# DMA register map
Vendor: Texas Instruments
Peripheral module from a debugger description file (folder DRA74xP_75xP_76xP_77xP).
Registers are 32-bit, access per field, reset 0x0 unless marked. A register's access mark holds for its fields unless they carry their own. Offsets are as the file gives them; lines under a group give offsets from that group; [hi:lo] are bit positions; {n}, {i} and the like mark numbered series; 'fields as' and 'values as' point back to an identical list; <NAME> marks a mode.

## DMA
0x00 SIMCOP_DMA_REVISION ro reset not defined — IP Revision Identifier (X.Y.R) Used by software to track features, bugs, and compatibility
  [31:0] REVISION — IP Revision
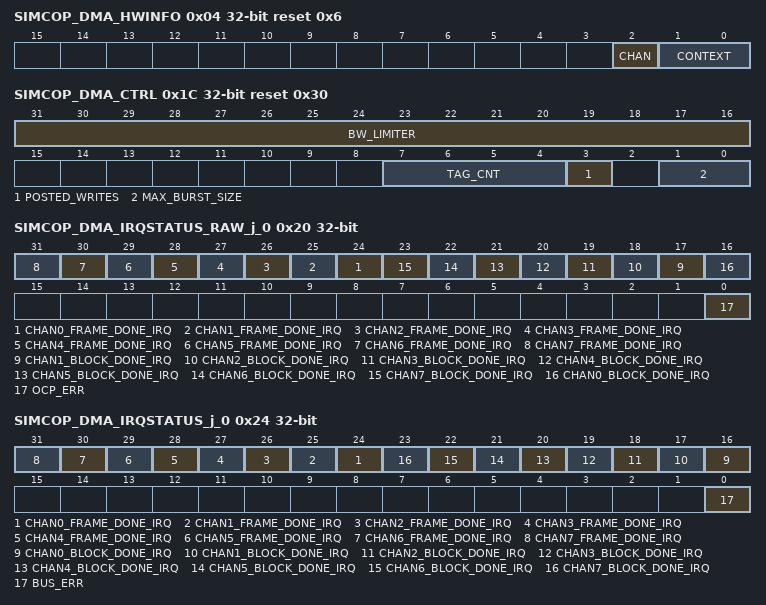
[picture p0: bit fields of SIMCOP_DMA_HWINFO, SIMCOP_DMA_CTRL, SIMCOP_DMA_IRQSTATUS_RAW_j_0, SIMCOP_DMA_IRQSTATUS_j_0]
0x04 SIMCOP_DMA_HWINFO ro reset 0x6 — Information about the IP module's hardware configuration, i.e. typically the module's HDL generics.
  [2] CHAN — Logical channels
    0=CHAN_0_r (4); 1=CHAN_1_r (8)
  [1:0] CONTEXT — Maximum outstanding OCP transactions
    0=CONTEXT_0_r (4); 1=CONTEXT_1_r (8); 2=CONTEXT_2_r (16)
0x10 SIMCOP_DMA_SYSCONFIG reset 0x20 — Clock management configuration
  [5:4] STANDBYMODE rw — Configuration of the local initiator state management mode. By definition, initiator may generate read/write transaction as long as it is out of STANDBY state.
    0=Force-standby mode: local initiator is unconditionally placed in standby state. Backup mode, for debug only.; 1=No-standby mode: local initiator is unconditionally placed out of standby state. Backup mode, for debug only.; 2=Smart_standby_mode; 3=Smart_standby_mode
0x18 SIMCOP_DMA_IRQ_EOI — End Of Interrupt number specification
  [1:0] LINE_NUMBER rw — Software End Of Interrupt (EOI) control. Write number of interrupt output.
    0=READ0 (Reads always 0 (no EOI memory)); 1=EOI1 (EOI for interrupt output line #1)
0x1C SIMCOP_DMA_CTRL reset 0x30
  [31:16] BW_LIMITER rw — SIMCOP DMA guarantees that there are at least BW_LIMITER functional clock cycles between two OCP requests. No IDLE cycles are inserted during an OCP transaction. This parameter could be used to reduce traffic generated by the SIMCOP DMA for non timing critical applications. Doing so leaves more BW for other system initiators. Default value corresponds to maximum performance.
  [7:4] TAG_CNT rw — Limits the outstanding transactions count. Only tags 0 - TAG_CNT will be used by SIMCOP DMA The maximum allowed value is 2
  [3] POSTED_WRITES rw — Select write type. Setting depend on the used interconnect
    0=Only_non_posted_writes_are_generated; 1=Only_posted_writes_are_generated
  [1:0] MAX_BURST_SIZE rw — Defines the maximum burst length for INCR bursts. In case of 2D bursts, length x height is less or equal to this value.
    0=Single_requests_only; 1=less_or_equal_to_2; 2=less_or_equal_to_4; 3=less_or_equal_to_8
0x20 SIMCOP_DMA_IRQSTATUS_RAW_j_0 access not given — Per-event raw interrupt status vector Raw status is set even if event is not enabled. Write 1 to set the (raw) status, mostly for debug.
  [all] fields
    0=No_action; 0=No_event_pending; 1=Event_pending; 1=Set_event_(debug)
  [n+24] CHAN{n}_FRAME_DONE_IRQ (n=0..7) — Channel has completed transfer of the full frame (access RW W1toSet)
  [n+16] CHAN{n}_BLOCK_DONE_IRQ (n=1..7) — Channel has completed transfer of one 2D block (access RW W1toSet)
  [16] CHAN0_BLOCK_DONE_IRQ rw — Channel has completed transfer of one 2D block
  [0] OCP_ERR — OCP error (access RW W1toSet)
0x24 SIMCOP_DMA_IRQSTATUS_j_0 access not given — Per-event 'enabled' interrupt status vector Enabled status isn't set unless event is enabled. Write 1 to clear the status after interrupt has been serviced (raw status gets cleared, i.e. even if not enabled).
  [all] fields
    0=No_action; 0=No_(enabled)_event_pending; 1=Event_pending; 1=Clear_(raw)_event
  [n+24] CHAN{n}_FRAME_DONE_IRQ (n=0..7) — Channel has completed transfer of the full frame (access RW W1toClr)
  [n+16] CHAN{n}_BLOCK_DONE_IRQ (n=0..7) — Channel has completed transfer of one 2D block (access RW W1toClr)
  [0] BUS_ERR — BUS error (access RW W1toClr)
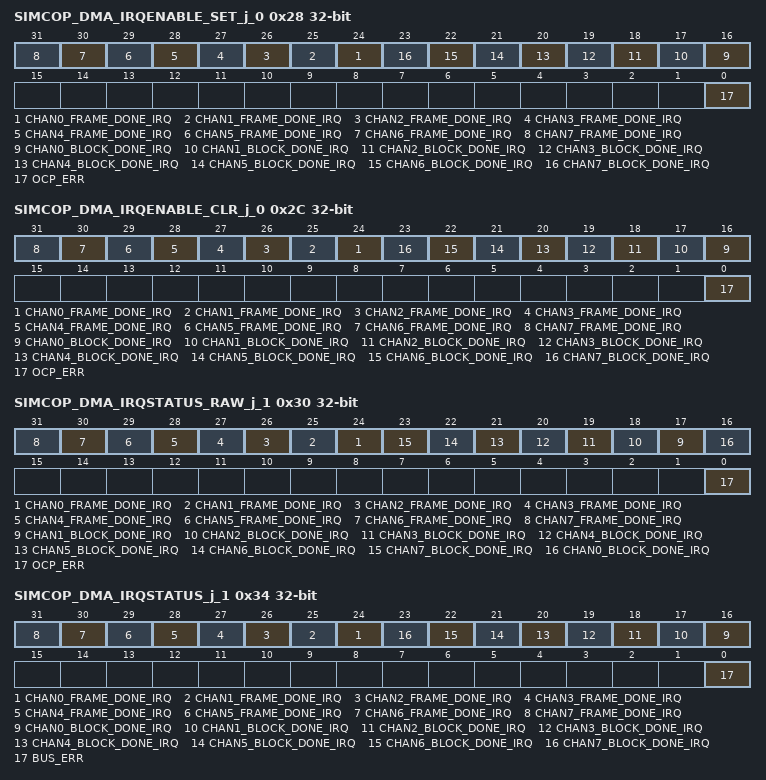
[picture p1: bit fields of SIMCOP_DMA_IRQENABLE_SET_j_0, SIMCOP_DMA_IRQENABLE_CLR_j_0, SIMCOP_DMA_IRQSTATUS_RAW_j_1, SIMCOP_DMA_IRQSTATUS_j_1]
0x28 SIMCOP_DMA_IRQENABLE_SET_j_0 access not given — Per-event interrupt enable bit vector Write 1 to set (enable interrupt). Readout equal to corresponding _CLR register.
  [all] fields
    0=No_action; 0=Interrupt_disabled_(masked); 1=Interrupt_enabled; 1=Enable_interrupt
  [n+24] CHAN{n}_FRAME_DONE_IRQ (n=0..7) — Channel has completed transfer of the full frame (access RW W1toSet)
  [n+16] CHAN{n}_BLOCK_DONE_IRQ (n=0..7) — Channel has completed transfer of one 2D block (access RW W1toSet)
  [0] OCP_ERR — OCP error (access RW W1toSet)
0x2C SIMCOP_DMA_IRQENABLE_CLR_j_0 access not given — Per-event interrupt enable bit vector Write 1 to clear (disable interrupt). Readout equal to corresponding _SET register.
  [all] fields
    0=No_action; 0=Interrupt_disabled_(masked); 1=Interrupt_enabled; 1=Disable_interrupt
  [n+24] CHAN{n}_FRAME_DONE_IRQ (n=0..7) — Channel has completed transfer of the full frame (access RW W1toClr)
  [n+16] CHAN{n}_BLOCK_DONE_IRQ (n=0..7) — Channel has completed transfer of one 2D block (access RW W1toClr)
  [0] OCP_ERR — OCP error (access RW W1toClr)
0x30 SIMCOP_DMA_IRQSTATUS_RAW_j_1 access not given — Per-event raw interrupt status vector Raw status is set even if event is not enabled. Write 1 to set the (raw) status, mostly for debug.
  fields as SIMCOP_DMA_IRQSTATUS_RAW_j_0
0x34 SIMCOP_DMA_IRQSTATUS_j_1 access not given — Per-event 'enabled' interrupt status vector Enabled status isn't set unless event is enabled. Write 1 to clear the status after interrupt has been serviced (raw status gets cleared, i.e. even if not enabled).
  fields as SIMCOP_DMA_IRQSTATUS_j_0
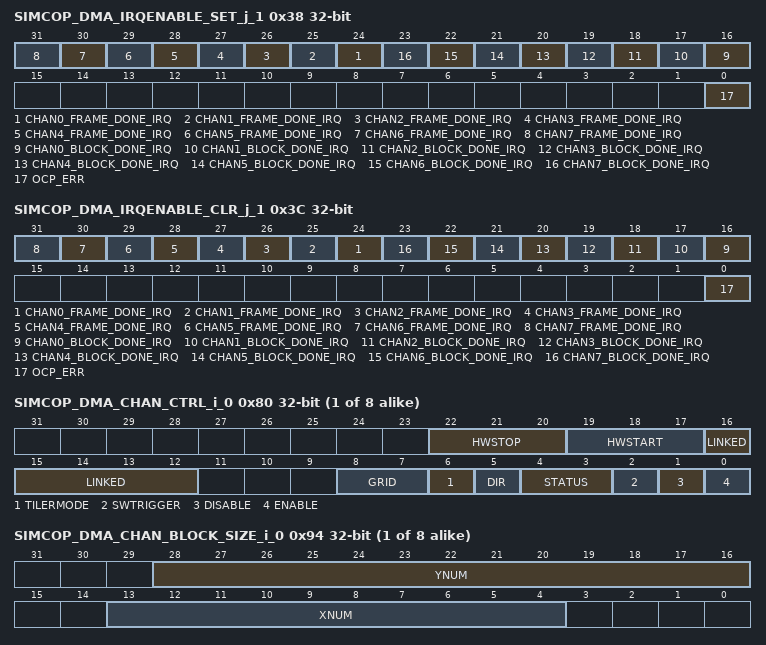
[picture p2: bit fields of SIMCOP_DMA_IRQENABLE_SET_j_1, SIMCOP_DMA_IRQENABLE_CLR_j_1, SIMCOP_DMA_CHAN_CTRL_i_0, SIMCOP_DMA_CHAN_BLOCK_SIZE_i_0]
0x38 SIMCOP_DMA_IRQENABLE_SET_j_1 access not given — Per-event interrupt enable bit vector Write 1 to set (enable interrupt). Readout equal to corresponding _CLR register.
  fields as SIMCOP_DMA_IRQENABLE_SET_j_0
0x3C SIMCOP_DMA_IRQENABLE_CLR_j_1 access not given — Per-event interrupt enable bit vector Write 1 to clear (disable interrupt). Readout equal to corresponding _SET register.
  fields as SIMCOP_DMA_IRQENABLE_CLR_j_0
{0x80+0x30*i} SIMCOP_DMA_CHAN_CTRL_i_{i} (reset mask 0xFFFFFE3F) (i=0..7) — Logical channel control register
  [22:20] HWSTOP rw — DMA logical channel HW synchronization. Controls generation of the DONE pulse for the logical channel Only the values listed below are allowed. Other values lead to undefined behavior.
    0=Disabled; {v}=Use_HW_synchronization_channel_{v-4} (v=4..7)
  [19:17] HWSTART rw — DMA logical channel HW synchronization. Controls sensitivity of the logical channel on a START pulse Only the values listed below are allowed. Other values lead to undefined behavior.
    values as HWSTOP
  [16:12] LINKED rw — DMA logical channel linking. Only the values listed below are allowed. Other values lead to undefined behavior.
    0=Disabled; {v}=2D_{v} (Start channel {v-16} when this channel has completed transfer of one 2D block) (v=16..23)
  [8:7] GRID rw — Selects the grid to be used when TILERMODE=1
    0=X=ADDR[13:0],_Y=ADDR[26:14]_0 (Subtile : 4x4 bytes Tile: 32x32 bytes X=ADDR[13:0], Y=ADDR[26:14]); 1=X=ADDR[12:0],_Y=ADDR[26:13]_1 (Subtile : 4x4 bytes Tile: 32x32 bytes X=ADDR[12:0], Y=ADDR[26:13]); 2=X=ADDR[14:0],_Y=ADDR[26:15]_2 (Subtile : 8x2 bytes Tile: 64x16 bytes X=ADDR[14:0], Y=ADDR[26:15]); 3=X=ADDR[13:0],_Y=ADDR[26:14]_3 (Subtile : 8x2 bytes Tile: 64x16 bytes X=ADDR[13:0], Y=ADDR[26:14])
  [6] TILERMODE rw — Selects OCP transaction breakdown algorithm
    0=INCR_ADDR[32]=0_OCP_0 (Regular mode. INCR burst are used. ADDR[32]=0 for OCP transactions); 1=BLCK_ADDR[32]=1_OCP_1 (Tiler mode. BLCK burst are used. ADDR[32]=1 for OCP transactions)
  [5] DIR rw — Transfer direction
    0=System_memory_-_SIMCOP_buffers; 1=SIMCOP_buffers_-_system_memory
  [4:3] STATUS ro — SW could poll this bit to know the state of the channel
    0=Idle; 1=Active; 2=Pending; 3=Running
  [2] SWTRIGGER wo — Software trigger of the DMA channel. Read of this register always returns 0.
    0=No_effect; 1=PENDING_ACTIVE_RUNNING,_PENDING_IDLE_1 (Change the logical channel state to PENDING if it is in ACTIVE state. No effect if the channel is in RUNNING, PENDING or IDLE state)
  [1] DISABLE wo — Disable control of the logical channel. Read of this register always returns 0.
    0=No_effect; 1=IDLE_ACTIVE_RUNNING_PENDING_1 (Disable the channel. Changes the logical channel state to IDLE when it is in ACTIVE state. Memorize a disable request when the channel is in RUNNING or PENDING state.)
  [0] ENABLE wo — Enable control of the logical channel. Read of this register always returns 0.
    0=No_effect; 1=IDLE_ACTIVE._1 (Enable the channel. Changes the state of the logical channel from IDLE to ACTIVE.)
{0x84+0x30*i} SIMCOP_DMA_CHAN_SMEM_ADDR_i_{i} (reset mask 0xF) (i=0..7) — System memory address
  [31:4] ADDR rw — Address in 128-bit words
{0x88+0x30*i} SIMCOP_DMA_CHAN_SMEM_OFST_i_{i} (reset mask 0xFFF0000F) (i=0..7) — System memory line offset in 128-bit words. Maximum stride = 1Mbyte
  [19:4] OFST rw — Line offset. In 128-bit words.
{0x8C+0x30*i} SIMCOP_DMA_CHAN_BUF_OFST_i_{i} (reset mask 0xFF00000F) (i=0..7) — SIMCOP memory line offset
  [23:4] OFST rw — Line offset. In 128-bit words.
{0x90+0x30*i} SIMCOP_DMA_CHAN_BUF_ADDR_i_{i} (reset mask 0xFF00000F) (i=0..7) — SIMCOP memory address
  [23:4] ADDR rw — Address in 128-bit words.
{0x94+0x30*i} SIMCOP_DMA_CHAN_BLOCK_SIZE_i_{i} (reset mask 0xE000C00F) (i=0..7) — 2D block size
  [28:16] YNUM rw — Height, in lines, per 2D block Valid values are 1- 8191.
  [13:4] XNUM rw — Width, in 128-bit words, per 2D block. Valid values are 1-1023, that corresponds to 16 bytes to 16kBytes.
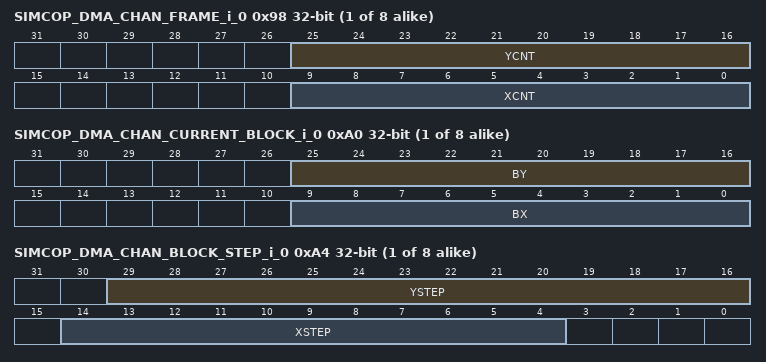
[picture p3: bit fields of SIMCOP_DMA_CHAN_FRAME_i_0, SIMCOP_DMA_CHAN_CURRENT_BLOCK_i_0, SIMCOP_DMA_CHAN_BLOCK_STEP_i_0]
{0x98+0x30*i} SIMCOP_DMA_CHAN_FRAME_i_{i} (reset mask 0xFC00FC00) (i=0..7) — Defines a frame. A frame is composed of 2D blocks.
  [25:16] YCNT rw — Vertical count of 2D blocks per frame. Valid values are 1-1023
  [9:0] XCNT rw — Horizontal count of 2D blocks per frame. Valid values are 1-1023
{0xA0+0x30*i} SIMCOP_DMA_CHAN_CURRENT_BLOCK_i_{i} ro (reset mask 0xFC00FC00) (i=0..7) — SW could read the coordinates of the last transferred block. The status is reset when the channel is enabled (change the state of CTRL.ENABLE from 0 to 1).
  [25:16] BY — Vertical position of the last transferred 2D block in the frame.
  [9:0] BX — Horizontal position of the last transferred 2D block in the frame.
{0xA4+0x30*i} SIMCOP_DMA_CHAN_BLOCK_STEP_i_{i} (reset mask 0xC000800F) (i=0..7) — Offset between 2D blocks.
  [29:16] YSTEP rw — Vertical offset, in lines, between rows of 2D blocks. For contiguous 2D blocks YSTEP=YNUM Valid values are -8192 to +8191.
  [14:4] XSTEP rw — Horizontal offset, in 128-bit words, between 2D block columns. For contiguous 2D blocks XSTEP=XNUM Valid values are -1024 to +1023, that corresponds to 16 bytes to 16kBytes.
